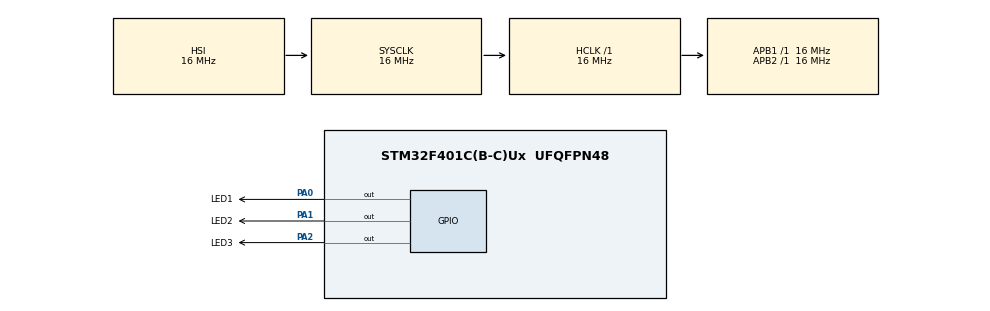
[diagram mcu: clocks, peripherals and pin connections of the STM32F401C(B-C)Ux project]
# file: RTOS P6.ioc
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FREERTOS.Tasks01=defaultTask,24,128,StartDefaultTask,Default,NULL,Dynamic,NULL,NULL;GreenLEDTask,8,128,green_led,Default,NULL,Dynamic,NULL,NULL;RedLEDTask,24,128,red_led,Default,NULL,Dynamic,NULL,NULL
FREERTOS.configUSE_NEWLIB_REENTRANT=1
Mcu.Family=STM32F4
Mcu.Name=STM32F401C(B-C)Ux
Mcu.Package=UFQFPN48
NVIC.PriorityGroup=NVIC_PRIORITYGROUP_4
NVIC.TIM4_IRQn=true\:15\:0\:false\:false\:true\:false\:false\:true\:true
NVIC.TimeBase=TIM4_IRQn
NVIC.TimeBaseIP=TIM4
PA0-WKUP.GPIO_Label=LED1
PA0-WKUP.Signal=GPIO_Output
PA1.GPIO_Label=LED2
PA1.Signal=GPIO_Output
PA13.Mode=Serial_Wire
PA13.Signal=SYS_JTMS-SWDIO
PA14.Mode=Serial_Wire
PA14.Signal=SYS_JTCK-SWCLK
PA2.GPIO_Label=LED3
PA2.Signal=GPIO_Output
ProjectManager.HeapSize=0x200
ProjectManager.StackSize=0x400
ProjectManager.TargetToolchain=STM32CubeIDE
RCC.AHBFreq_Value=16000000
RCC.APB1Freq_Value=16000000
RCC.APB2Freq_Value=16000000
RCC.CortexFreq_Value=16000000
RCC.HSE_VALUE=25000000
RCC.HSI_VALUE=16000000
RCC.LSE_VALUE=32768
RCC.SYSCLKFreq_VALUE=16000000
RCC.VCOOutputFreq_Value=192000000
VP_FREERTOS_VS_CMSIS_V2.Mode=CMSIS_V2
VP_SYS_VS_tim4.Mode=TIM4
board=custom

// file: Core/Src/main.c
/* USER CODE BEGIN Header */
/**
  ******************************************************************************
  * @file           : main.c
  * @brief          : Main program body
  ******************************************************************************
  * @attention
  *
  * Copyright (c) 2024 STMicroelectronics.
  * All rights reserved.
  *
  * This software is licensed under terms that can be found in the LICENSE file
  * in the root directory of this software component.
  * If no LICENSE file comes with this software, it is provided AS-IS.
  *
  ******************************************************************************
  */
/* USER CODE END Header */
#include "main.h"
#include "cmsis_os.h"

/* USER CODE BEGIN Includes */
#include "DWT_Delay.h"

/* USER CODE END Includes */

/* Definitions for defaultTask */
osThreadId_t defaultTaskHandle;
const osThreadAttr_t defaultTask_attributes = {
  .name = "defaultTask",
  .stack_size = 128 * 4,
  .priority = (osPriority_t) osPriorityNormal,
};
/* Definitions for GreenLEDTask */
osThreadId_t GreenLEDTaskHandle;
const osThreadAttr_t GreenLEDTask_attributes = {
  .name = "GreenLEDTask",
  .stack_size = 128 * 4,
  .priority = (osPriority_t) osPriorityLow,
};
/* Definitions for RedLEDTask */
osThreadId_t RedLEDTaskHandle;
const osThreadAttr_t RedLEDTask_attributes = {
  .name = "RedLEDTask",
  .stack_size = 128 * 4,
  .priority = (osPriority_t) osPriorityNormal,
};

void SystemClock_Config(void);
static void MX_GPIO_Init(void);
void StartDefaultTask(void *argument);
void green_led(void *argument);
void red_led(void *argument);

/* USER CODE BEGIN PFP */
/* USER CODE BEGIN PFP */
uint32_t millis (void) {
    return DWT->CYCCNT / (HAL_RCC_GetHCLKFreq() / 1000);
}
uint32_t start;
void Delay_ms(uint32_t milliseconds) {
    start = millis();

    while (millis() - start < milliseconds) {
        // Wait until the required time has passed
    	__NOP();
    }
}

uint8_t flagg = 1;
void accessData(){
	taskENTER_CRITICAL();
	if(flagg == 1) flagg = 0;
	else{
		HAL_GPIO_WritePin(LED1_GPIO_Port, LED1_Pin, 1); //LED YELLOW
//		osDelay(100);
//		HAL_Delay(100);
		Delay_ms(100);
		HAL_GPIO_WritePin(LED1_GPIO_Port, LED1_Pin, 0);
	}
//	HAL_Delay(500);
	Delay_ms(500);
	flagg = 1;
	taskEXIT_CRITICAL();
}

/* USER CODE END PFP */

int main(void)
{

  /* MCU Configuration--------------------------------------------------------*/

  /* Reset of all peripherals, Initializes the Flash interface and the Systick. */
  HAL_Init();

  /* USER CODE BEGIN Init */
   DWT_Delay_Init();
  /* USER CODE END Init */

  /* Configure the system clock */
  SystemClock_Config();

  /* Initialize all configured peripherals */
  MX_GPIO_Init();
  /* USER CODE BEGIN 2 */
    HAL_GPIO_WritePin(LED1_GPIO_Port, LED1_Pin, 0);//LED YELLOW
  /* USER CODE END 2 */

  /* Init scheduler */
  osKernelInitialize();

  /* Create the thread(s) */
  /* creation of defaultTask */
  defaultTaskHandle = osThreadNew(StartDefaultTask, NULL, &defaultTask_attributes);

  /* creation of GreenLEDTask */
  GreenLEDTaskHandle = osThreadNew(green_led, NULL, &GreenLEDTask_attributes);

  /* creation of RedLEDTask */
  RedLEDTaskHandle = osThreadNew(red_led, NULL, &RedLEDTask_attributes);

  /* Start scheduler */
  osKernelStart();

  /* We should never get here as control is now taken by the scheduler */

  /* Infinite loop */
  while (1)
  {

  }
}

void SystemClock_Config(void)
{
  RCC_OscInitTypeDef RCC_OscInitStruct = {0};
  RCC_ClkInitTypeDef RCC_ClkInitStruct = {0};

  /** Configure the main internal regulator output voltage
  */
  __HAL_RCC_PWR_CLK_ENABLE();
  __HAL_PWR_VOLTAGESCALING_CONFIG(PWR_REGULATOR_VOLTAGE_SCALE2);

  /** Initializes the RCC Oscillators according to the specified parameters
  * in the RCC_OscInitTypeDef structure.
  */
  RCC_OscInitStruct.OscillatorType = RCC_OSCILLATORTYPE_HSI;
  RCC_OscInitStruct.HSIState = RCC_HSI_ON;
  RCC_OscInitStruct.HSICalibrationValue = RCC_HSICALIBRATION_DEFAULT;
  RCC_OscInitStruct.PLL.PLLState = RCC_PLL_NONE;
  if (HAL_RCC_OscConfig(&RCC_OscInitStruct) != HAL_OK)
  {
    Error_Handler();
  }

  /** Initializes the CPU, AHB and APB buses clocks
  */
  RCC_ClkInitStruct.ClockType = RCC_CLOCKTYPE_HCLK|RCC_CLOCKTYPE_SYSCLK
                              |RCC_CLOCKTYPE_PCLK1|RCC_CLOCKTYPE_PCLK2;
  RCC_ClkInitStruct.SYSCLKSource = RCC_SYSCLKSOURCE_HSI;
  RCC_ClkInitStruct.AHBCLKDivider = RCC_SYSCLK_DIV1;
  RCC_ClkInitStruct.APB1CLKDivider = RCC_HCLK_DIV1;
  RCC_ClkInitStruct.APB2CLKDivider = RCC_HCLK_DIV1;

  if (HAL_RCC_ClockConfig(&RCC_ClkInitStruct, FLASH_LATENCY_0) != HAL_OK)
  {
    Error_Handler();
  }
}

static void MX_GPIO_Init(void)
{
  GPIO_InitTypeDef GPIO_InitStruct = {0};

  /* GPIO Ports Clock Enable */
  __HAL_RCC_GPIOA_CLK_ENABLE();

  /*Configure GPIO pin Output Level */
  HAL_GPIO_WritePin(GPIOA, LED1_Pin|LED2_Pin|LED3_Pin, GPIO_PIN_RESET);

  /*Configure GPIO pins : LED1_Pin LED2_Pin LED3_Pin */
  GPIO_InitStruct.Pin = LED1_Pin|LED2_Pin|LED3_Pin;
  GPIO_InitStruct.Mode = GPIO_MODE_OUTPUT_PP;
  GPIO_InitStruct.Pull = GPIO_NOPULL;
  GPIO_InitStruct.Speed = GPIO_SPEED_FREQ_LOW;
  HAL_GPIO_Init(GPIOA, &GPIO_InitStruct);

}

void StartDefaultTask(void *argument)
{
  for(;;)
  {
    osDelay(1);
  }
}

void green_led(void *argument)
{
  /* USER CODE BEGIN green_led */
  /* Infinite loop */
	 for(;;)
	  {
		  HAL_GPIO_WritePin(GPIOA, GPIO_PIN_2, 1);
		  accessData();
		  HAL_GPIO_WritePin(GPIOA, GPIO_PIN_2, 0);
		  osDelay(500);
	  }
  /* USER CODE END green_led */
}

void red_led(void *argument)
{
  /* USER CODE BEGIN red_led */
  /* Infinite loop */
	 for(;;)
	  {
		  HAL_GPIO_WritePin(GPIOA, GPIO_PIN_0, 1);
		  accessData();
		  HAL_GPIO_WritePin(GPIOA, GPIO_PIN_0, 0);
		  osDelay(100);
	  }
  /* USER CODE END red_led */
}

void HAL_TIM_PeriodElapsedCallback(TIM_HandleTypeDef *htim)
{
  if (htim->Instance == TIM4) {
    HAL_IncTick();
  }
}

void Error_Handler(void)
{
  __disable_irq();
  while (1)
  {
  }
}
